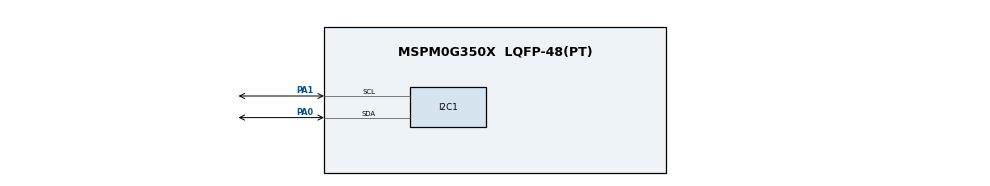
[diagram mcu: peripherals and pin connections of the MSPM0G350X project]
/**
 *
 * @cliArgs --device "MSPM0G350X" --part "Default" --package "LQFP-48(PT)" --product "mspm0_sdk@2.11.00.07"
 * @versions {"tool":"1.28.0+4712"}
 */

/**
 * Import the modules used in this configuration.
 */
const I2C  = scripting.addModule("/ti/driverlib/I2C", {}, false);
const I2C1 = I2C.addInstance();

/**
 * Write custom configuration values to the imported modules.
 */
I2C1.$name                             = "OLED_I2C";
I2C1.basicEnableController             = true;
I2C1.peripheral.$assign                = "I2C0";
I2C1.peripheral.sdaPin.$assign         = "PA0";
I2C1.peripheral.sclPin.$assign         = "PA1";
I2C1.sdaPinConfig.$name                = "ti_driverlib_gpio_GPIOPinGeneric0";
I2C1.sdaPinConfig.hideOutputInversion  = scripting.forceWrite(false);
I2C1.sdaPinConfig.onlyInternalResistor = scripting.forceWrite(false);
I2C1.sdaPinConfig.passedPeripheralType = scripting.forceWrite("Digital");
I2C1.sclPinConfig.$name                = "ti_driverlib_gpio_GPIOPinGeneric1";
I2C1.sclPinConfig.hideOutputInversion  = scripting.forceWrite(false);
I2C1.sclPinConfig.onlyInternalResistor = scripting.forceWrite(false);
I2C1.sclPinConfig.passedPeripheralType = scripting.forceWrite("Digital");

const Board = scripting.addModule("/ti/driverlib/Board", {}, false);

const SYSCTL = scripting.addModule("/ti/driverlib/SYSCTL", {}, false);

/**
 * Pinmux solution for unlocked pins/peripherals. This ensures that minor changes to the automatic solver in a future
 * version of the tool will not impact the pinmux you originally saw.  These lines can be completely deleted in order to
 * re-solve from scratch.
 */
Board.peripheral.$suggestSolution          = "DEBUGSS";
Board.peripheral.swclkPin.$suggestSolution = "PA20";
Board.peripheral.swdioPin.$suggestSolution = "PA19";
SYSCTL.peripheral.$suggestSolution         = "SYSCTL";
